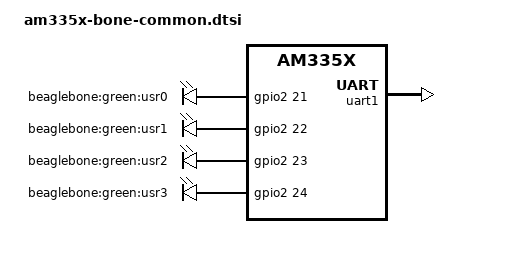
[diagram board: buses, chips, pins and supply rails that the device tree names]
                uart1: serial@44e09000 {
                        status = "okay";
                };

                gpio-leds {
                        compatible = "gpio-leds";
                        pinctrl-names = "default";
                        pinctrl-0 = <&userled_pins>;

                        led0 {
                                label = "beaglebone:green:usr0";
                                gpios = <&gpio2 21 0>;
                                linux,default-trigger = "heartbeat";
                                default-state = "off";
                        };

                        led1 {
                                label = "beaglebone:green:usr1";
                                gpios = <&gpio2 22 0>;
                                linux,default-trigger = "mmc0";
                                default-state = "off";
                        };

                        led2 {
                                label = "beaglebone:green:usr2";
                                gpios = <&gpio2 23 0>;
                                linux,default-trigger = "cpu0";
                                default-state = "off";
                        };

                        led3 {
                                label = "beaglebone:green:usr3";
                                gpios = <&gpio2 24 0>;
                                default-state = "off";
                                linux,default-trigger = "mmc1";
                        };
                };
